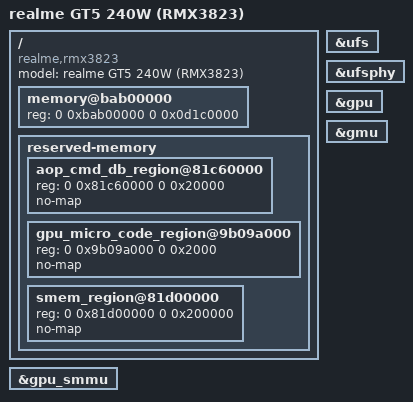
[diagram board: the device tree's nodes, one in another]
/dts-v1/;
/include/ "sm8550.dtsi"

/*
 * realme GT5 240W (RMX3823), Qualcomm kalama / SM8550.
 *
 * Verified on the device (adb, user build, no root):
 *   soc_id 519, machine KALAMA, revision 2.0, page size 4096
 *   8 cores: 3x A510 + 2x A710 + 2x A715 + 1x X3
 *   GPU Adreno740v2, 23645600 kB MemTotal, panel 1240x2772 @ 560 dpi
 *
 * Board overlay reference: dtbo entry 1/2 of the stock dtbo.img
 * ("Qualcomm Technologies, Inc. Kalama MTP,zonda-A/B"), whose qcom,msm-id
 * contains 0x207 (519). 167 fragments: PM8550/PM8550B/PM8550VE_F/PM8550VS/
 * PM8010/PMK8550/PMR735D regulators, MDSS DSI ctrl0/1 and PHY0/1.
 *
 * Values marked REQUIRED are not established yet and must not be trusted.
 */

/ {
    model = "realme GT5 240W (RMX3823)";
    compatible = "realme,rmx3823", "qcom,sm8550";

    /* The handoff range XNU receives as /chosen/dram-base and /chosen/dram-size.
     *
     * The ADT generator reads exactly one contiguous `device_type = "memory"`
     * range and rejects anything else, so this node is the whole of XNU's
     * physical memory - not a description of installed RAM.
     *
     * 0xBAB00000 + 0x0D1C0000 is the "DXE Heap" entry of the board's own
     * uefiplatLA.cfg, and it is the only region in that map marked
     * EFI_RESOURCE_SYSTEM_MEMORY with EfiConventionalMemory. Everything else is
     * reserved, no-map, or the vendor's kernel window. It sits above the
     * "Display Reserved" carveout (ends 0xBAB00000) and below "TZApps Reserved"
     * (starts 0xD8800000), so it overlaps nothing.
     *
     * Why not all 24 GiB: the firmware carveouts are interleaved through the
     * low address space - gunyah_hyp at 0x80000000, SMEM and AOP around
     * 0x81C00000, PIL Reserved 0x8A800000..0xA2A80000, the vendor kernel
     * window 0xA8000000..0xB8000000, TZApps at 0xD8800000 - and there is no
     * single contiguous range covering the rest. The vendor kernel window is
     * specifically the wrong choice: it is where ABL loads the boot image, and
     * this device's boot partition is 192 MiB, matching payload.size_mib.
     * Handing that range to XNU would have it overwrite the payload it is
     * reading.
     *
     * Widening this needs the booter to exclude the carveouts from the handoff,
     * which is not verified. 210 MiB is enough to bring up, and being wrong here
     * corrupts firmware memory rather than failing cleanly, so it errs small. */
    memory@bab00000 {
        device_type = "memory";
        reg = <0 0xbab00000 0 0x0d1c0000>;
    };

    /* NOTE: the nodes below are documentation, not protection.
     *
     * The ADT generator does not convert reserved-memory into ADT reservations;
     * /chosen/memory-map only ever carries RAMDisk, TrustCache, GpuAddon and
     * RootPolicies. They are kept because the addresses are verified and because
     * ShengGmuCommandDbInputs and the GPU driver need to name these regions, but
     * XNU is not kept out of them by their presence here - the handoff range
     * above is what does that. */
    reserved-memory {
        #address-cells = <2>;
        #size-cells = <2>;
        ranges;

        /* Command DB that ShengGmuCommandDbInputs parses. 0x81C60000 is read
         * from the device; the size follows from the firmware map, where "AOP"
         * is 0x81C00000 + 0xA0000 and aop_config_merged@81c80000 begins
         * immediately after this region. */
        aop_cmd_db_region@81c60000 {
            reg = <0 0x81c60000 0 0x20000>;
            no-map;
        };

        /* GPU microcode (ZAP) region. Address is read from the device. The
         * firmware map places it inside "PIL Reserved" 0x8A800000 + 0x18280000,
         * which says nothing about this node's own extent.
         * REQUIRED: confirm the size before enabling the GPU. */
        gpu_micro_code_region@9b09a000 {
            reg = <0 0x9b09a000 0 0x2000>;
            no-map;
        };

        /* SMEM. The firmware map gives this exactly: "SMEM" 0x81D00000 +
         * 0x00200000. The previous 0x400000 was wrong and would have swallowed
         * adsp_mhi@81f00000, which starts where SMEM ends. */
        smem_region@81d00000 {
            reg = <0 0x81d00000 0 0x200000>;
            no-map;
        };
    };
};

/*
 * Region inventory, reconciled against the firmware map.
 *
 * The device's /sys/firmware/devicetree/base/reserved-memory lists 28 regions
 * with addresses but no sizes. The board's uefiplatLA.cfg gives sizes for the
 * ones UEFI cares about, and they fall into three groups:
 *
 * Covered by a firmware-map entry, so the size is now known:
 *   gunyah_hyp@80000000, cpusys_vm@80a00000   -> "NOMAP" 0x80000000 + 0x1200000
 *   xbl_dt_log_merged@81a00000                -> "XBL DT" 0x81A00000 + 0x40000
 *   aop_config_merged@81c80000                -> inside "AOP" 0x81C00000 + 0xA0000
 *   llcc_lpi@ff800000                         -> "NOMAP" 0xFF800000 + 0x800000
 *
 * Covered collectively by "PIL Reserved" 0x8A800000 + 0x18280000, so the
 * individual extents are still unknown but the enclosing range is not:
 *   mpss@89800000 is the exception - it sits *below* 0x8A800000 and is not
 *   covered by any entry. The rest all fall inside:
 *   q6_mpss_dtb@9b000000, ipa_fw@9b080000, ipa_gsi@9b090000, spss@9b100000,
 *   camera@9b300000, video@9bb00000, cvp@9c200000, cdsp@9c900000,
 *   q6_cdsp_dtb@9e900000, q6_adsp_dtb@9e980000, adspslpi@9ea00000
 *
 * In the gaps the firmware map does not describe at all - these are the ones
 * that matter, because nothing in the UEFI map reserves them:
 *   chipinfo@81cf4000, adsp_mhi@81f00000, global_sync@82600000,
 *   tz_stat@82700000, mpss@89800000, mpss_dsm@d4d00000, xbl_sc@d8100000,
 *   cpucp_fw@d8140000, qtee@d8300000, oem_vm@f7c00000,
 *   oem_vm_swiotlb@f7b00000, trust_ui_vm@f3800000.
 *
 * The second group is why the handoff range above stops at 0xC7CC0000: it is
 * clear of every one of them. None of this is exercised by the current build,
 * since the ADT does not carry reserved-memory.
 */

/* Shared nodes are disabled in sm8550.dtsi; this board enables them. */
&ufs {
    status = "okay";
};

&ufsphy {
    status = "okay";
};

&gpu {
    status = "okay";
};

&gmu {
    status = "okay";
};

&gpu_smmu {
    status = "okay";
};
